# headsail register map
Vendor: tuni.fi; File version: 1.0
CPU: other r1p0, little endian, no MPU, no FPU, vendor SysTick, 2 interrupt priority bits
Registers are 32-bit, read-write, no defined reset value unless marked. A register's access mark holds for its fields unless they carry their own. Offsets are from the block's base; [hi:lo] are bit positions; lines under a group give offsets from that group; {n}, {i} and the like mark numbered series; 'fields as' and 'values as' point back to an identical list.

## SYSCTRL
Base 0x00101000
0x00 GPIO group
  0x00 DIR — GPIO direction configuration bitfield: - bit[i]=1b0: Input mode for GPIO[i] - bit[i]=1b1: Output mode for GPIO[i]
  0x04 EN — GPIO clock enable config register. Bit 31 - 0 GPIOEN (R/W) GPIO[31:0] clock enable configuration bitfield: - bit[i]=1b0: disable clock for GPIO[i] - bit[i]=1b1: enable clock for GPIO[i] GPIOs are gathered by groups of 4. The clock gating of one group is done only if all 4 GPIOs are disabled. Clock must be enabled for a GPIO if its direction is configured in input mode.
    [31:0] GPIOEN
  0x08 IN ro — GPIO Data IN register. Bit 31 - 0 DATA_IN (R) GPIO[31:0] input data read bitfield. DATA_IN[i] corresponds to input data of GPIO[i].
    [31:0] DATA_IN
  0x0C OUT — GPIO Data out register. Bit 31 - 0 DATA_OUT (R/W) GPIO[31:0] output data read bitfield. DATA_OUT[i] corresponds to output data set on GPIO[i].
    [31:0] DATA_OUT
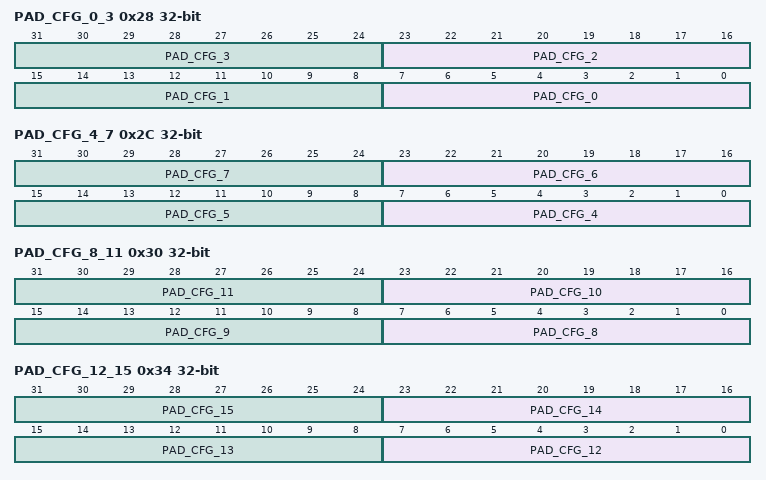
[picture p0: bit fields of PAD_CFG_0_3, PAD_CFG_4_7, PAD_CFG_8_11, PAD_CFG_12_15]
  0x28 PAD_CFG_0_3
    [8n+7:8n] PAD_CFG_{n} (n=0..3)
  0x2C PAD_CFG_4_7
    [8n-25:8n-32] PAD_CFG_{n} (n=4..7)
  0x30 PAD_CFG_8_11
    [8n-57:8n-64] PAD_CFG_{n} (n=8..11)
  0x34 PAD_CFG_12_15
    [8n-89:8n-96] PAD_CFG_{n} (n=12..15)
0x1000 UDMA group
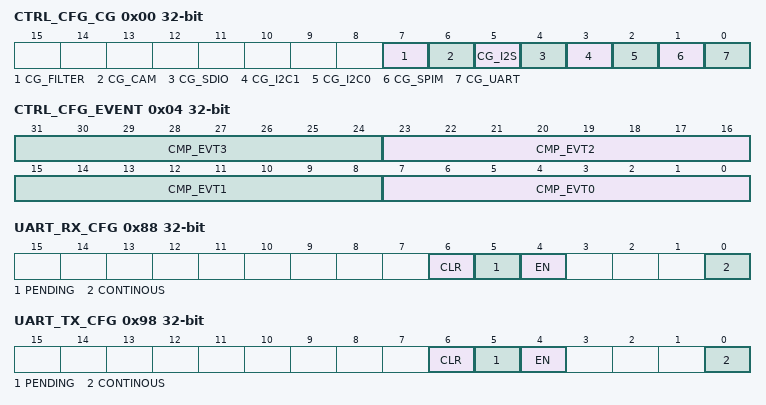
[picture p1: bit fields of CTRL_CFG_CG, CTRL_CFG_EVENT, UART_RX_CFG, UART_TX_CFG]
  0x00 CTRL_CFG_CG — uDMA peripherals clock gate configuration Bitfields Defines uDMA peripherals clock gate configuration for corresponding peripheral
    [7] CG_FILTER, [6] CG_CAM, [5] CG_I2S, [4] CG_SDIO, [3] CG_I2C1, [2] CG_I2C0, [1] CG_SPIM, [0] CG_UART
  0x04 CTRL_CFG_EVENT — uDMA peripherals external event configuration
    [8n+7:8n] CMP_EVT{n} (n=0..3) — Forward event with ID matching CMP_EVT{n} to peripherals as event{n}
  0x08 CTRL_CFG_RST — uDMA peripherals reset trigger (unimplemented)
  0x80 UART_RX_SADDR — uDMA RX UART buffer base address configuration register
    [31:0] RX_SADDR — RX buffer base address bitfield: - Read: returns value of the buffer pointer until transfer is finished. Else returns 0. - Write: sets RX buffer base address
  0x84 UART_RX_SIZE — uDMA RX UART buffer size configuration register
    [16:0] RX_SIZE — RX buffer size bitfield in bytes. (128kBytes maximum) - Read: returns remaining buffer size to transfer. - Write: sets buffer size.
  0x88 UART_RX_CFG — uDMA RX UART stream configuration register
    [6] CLR wo — RX channel clear and stop transfer: -1'b0: disable -1'b1: stop and clear the on-going transfer
    [5] PENDING ro
    [4] EN — RX channel enable and start transfer bitfield: -1'b0: disable -1'b1: enable and start the transfer This signal is used also to queue a transfer if one is already ongoing.
    [0] CONTINOUS — RX channel continuous mode bitfield: -1'b0: disabled -1'b1: enabled At the end of the buffer transfer, the uDMA reloads the address / buffer size and starts a new transfer.
  0x90 UART_TX_SADDR — uDMA TX UART buffer base address configuration register.
    [31:0] TX_SADDR — TX buffer base address bitfield: - Read: returns value of the buffer pointer until transfer is finished. Else returns 0. - Write: sets buffer base address
  0x94 UART_TX_SIZE — uDMA TX UART buffer size configuration register
    [16:0] TX_SIZE — TX buffer size bitfield in bytes. (128kBytes maximum) - Read: returns remaining buffer size to transfer. - Write: sets buffer size.
  0x98 UART_TX_CFG — uDMA TX UART stream configuration register.
    [6] CLR wo — RX channel clear and stop transfer: -1'b0: disable -1'b1: stop and clear the on-going transfer
    [5] PENDING ro — TX transfer pending in queue status flag: -1'b0: no pending transfer in the queue -1'b1: pending transfer in the queue
    [4] EN — TX channel enable and start transfer bitfield: -1'b0: disabled -1'b1: enable and start the transfer This signal is used also to queue a transfer if one is already ongoing.
    [0] CONTINOUS — TX channel continuous mode bitfield: -1'b0: disabled -1'b1: enabled At the end of the buffer transfer, the uDMA reloads the address / buffer size and starts a new transfer.
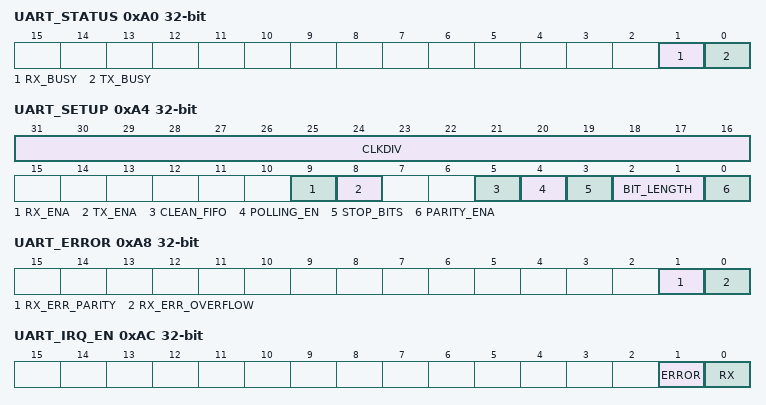
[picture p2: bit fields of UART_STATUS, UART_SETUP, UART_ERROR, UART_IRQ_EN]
  0xA0 UART_STATUS ro — uDMA UART status register
    [1] RX_BUSY — RX busy status flag: - 1'b0: no RX transfer on-going - 1'b1: RX transfer on-going
    [0] TX_BUSY — TX busy status flag: - 1'b0: no TX transfer on-going - 1'b1: TX transfer on-going
  0xA4 UART_SETUP — UDMA UART configuration register.
    [31:16] CLKDIV — UART Clock divider configuration bitfield. The baudrate is equal to SOC_FREQ/CLKDIV.
    [9] RX_ENA — RX transceiver configuration bitfield: - 1'b0: disabled - 1'b1: enabled
    [8] TX_ENA — TX transceiver configuration bitfield: - 1'b0: disabled - 1'b1: enabled
    [5] CLEAN_FIFO — In all mode clean the RX fifo, set 1 then set 0 to realize a reset fifo: - 1'b0: Stop Clean the RX FIFO. - 1'b1: Clean the RX FIFO.
    [4] POLLING_EN — When in uart read, use polling method to read the data, read interrupt enable flag will be ignored: - 1'b0: Do not using polling method to read data. - 1'b1: Using polling method to read data. Interrupt enable flag will be ignored.
    [3] STOP_BITS — Stop bits length bitfield: - 1'b0: 1 stop bit - 1'b1: 2 stop bits
    [2:1] BIT_LENGTH — Character length bitfield: - 2'b00: 5 bits - 2'b01: 6 bits - 2'b10: 7 bits - 2'b11: 8 bits
    [0] PARITY_ENA — Parity bit generation and check configuration bitfield: - 1'b0: disabled - 1'b1: enabled
  0xA8 UART_ERROR ro — uDMA UART Error status
    [1] RX_ERR_PARITY — RX parity error status flag: - 1'b0: no error - 1'b1: RX parity error occurred
    [0] RX_ERR_OVERFLOW — RX overflow error status flag: - 1'b0: no error - 1'b1: RX overflow error occurred
  0xAC UART_IRQ_EN — uDMA UART Read or Error interrupt enable register
    [1] ERROR — Error interrupt in enable flag: - 1'b0: Error IRQ disable - 1'b1: Error IRQ enable
    [0] RX — Rx interrupt in enable flag: - 1'b0: RX IRQ disable - 1'b1: RX IRQ enable
  0xB0 UART_VALID ro — uDMA UART Read polling data valid flag register
    [0] READY — Used only in RX polling method to indicate data is ready for read: - 1'b0: Data is not ready to read - 1'b1: Data is ready to read
  0xB4 UART_DATA ro — RX read data for polling or interrupt
    [7:0] BYTE
  0x100 SPIM_RX_SADDR — RX SPI uDMA transfer address of associated buffer
    [31:0] RX_SADDR — Configure pointer to memory buffer: - Read: value of the pointer until transfer is over. Else returns 0 - Write: set Address Pointer to memory buffer start address
  0x104 SPIM_RX_SIZE — RX SPI uDMA transfer size of buffer
    [19:0] RX_SIZE — Buffer size in bytes. (1MBytes maximum) - Read: buffer size left - Write: set buffer size
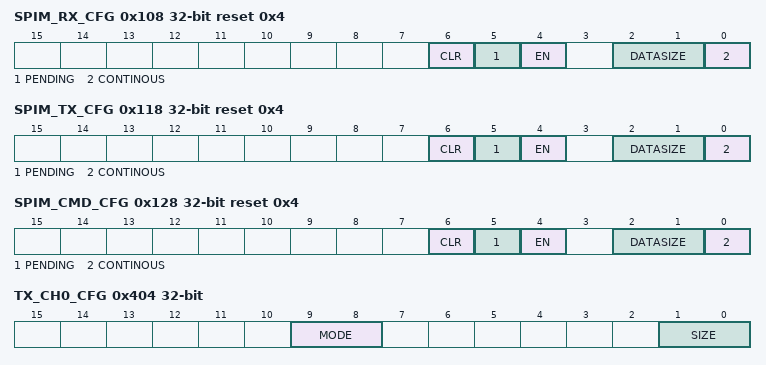
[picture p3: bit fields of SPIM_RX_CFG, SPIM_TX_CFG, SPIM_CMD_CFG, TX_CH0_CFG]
  0x108 SPIM_RX_CFG reset 0x4 (reset mask 0x0) — RX SPI uDMA transfer configuration
    [6] CLR wo — Channel clear and stop transfer: -1'b0: disable -1'b1: enable
    [5] PENDING ro — Transfer pending in queue status flag: -1'b0: free -1'b1: pending
    [4] EN — Channel enable and start transfer: -1'b0: disable -1'b1: enable This signal is used also to queue a transfer if one is already ongoing
    [2:1] DATASIZE — Channel transfer size used to increment uDMA buffer address pointer: - 2'b00: +1 (8 bits) - 2'b01: +2 (16 bits) - 2'b10: +4 (
      0=8BITS; 1=16BITS; 2=32BITS
    [0] CONTINOUS — Channel continuous mode: -1'b0: disable -1'b1: enable At the end of the buffer the uDMA reloads the address and size and starts a new transfer.
  0x110 SPIM_TX_SADDR — TX SPI uDMA transfer address of associated buffer
    [31:0] TX_SADDR — Configure pointer to memory buffer: - Read: value of the pointer until transfer is over. Else returns 0 - Write: set Address Pointer to memory buffer start address
  0x114 SPIM_TX_SIZE — TX SPI uDMA transfer size of buffer
    [19:0] TX_SIZE — Buffer size in bytes. (1MBytes maximum) - Read: buffer size left - Write: set buffer size
  0x118 SPIM_TX_CFG reset 0x4 (reset mask 0x0) — TX SPI uDMA transfer configuration
    fields as UDMA.SPIM_RX_CFG
  0x120 SPIM_CMD_SADDR — CMD SPI uDMA transfer address of associated buffer
    [31:0] CMD_SADDR — Configure pointer to memory buffer: - Read: value of the pointer until transfer is over. Else returns 0 - Write: set Address Pointer to memory buffer start address
  0x124 SPIM_CMD_SIZE — CMD SPI uDMA transfer size of buffer
    [19:0] CMD_SIZE — Buffer size in bytes. (1MBytes maximum) - Read: buffer size left - Write: set buffer size
  0x128 SPIM_CMD_CFG reset 0x4 (reset mask 0x0) — CMD SPI uDMA transfer configuration
    fields as UDMA.SPIM_RX_CFG
  0x400 TX_CH0_ADD — FILTER tx channel address register
    [31:0] REG_TX_CH0_ADD
  0x404 TX_CH0_CFG — FILTER tx channel configuration register
    [9:8] MODE — Data transfer mode: - 2'b00: Linear - 2'b01: Sliding - 2;b10:Circular - 2;b11:2D
      0=LINEAR; 1=SLIDING; 2=CIRCULAR; 3=2D
    [1:0] SIZE — Data transfer format: - 2'b00: 8-bit - 2'b01:16-bit - 2;b10:32-bit
      0=8BITS; 1=16BITS; 2=32BITS
  0x408 TX_CH0_LEN0 — FILTER tx channel length1 register
    [31:0] REG_TX_CH0_ADD
  0x40C TX_CH0_LEN1 — FILTER tx channel length2 register
    [31:0] REG_TX_CH0_LEN1
  0x410 TX_CH0_LEN2 — FILTER tx channel 0 length2 register
    [31:0] REG_TX_CH0_LEN2
  0x414 TX_CH1_ADD — FILTER tx channel address register
    [31:0] REG_TX_CH1_ADD
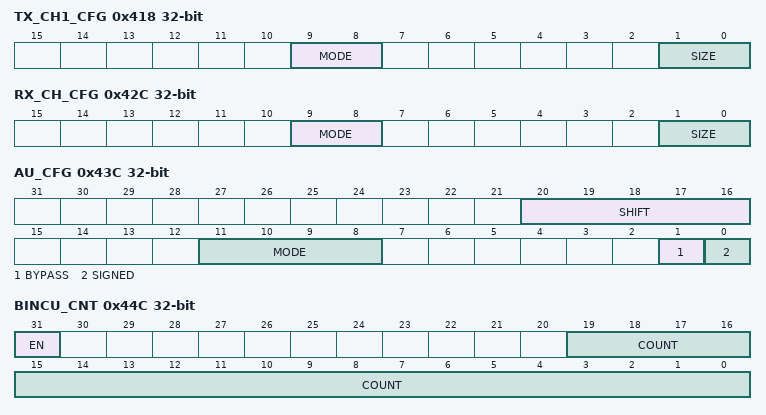
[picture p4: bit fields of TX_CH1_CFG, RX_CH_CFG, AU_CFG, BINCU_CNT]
  0x418 TX_CH1_CFG — FILTER tx channel configuration register
    [9:8] MODE — Data transfer mode: - 2'b00: Linear - 2'b01: Sliding - 2;b10:Circular - 2;b11:2D
      1=SLIDING; 0=LINEAR; 2=CIRCULAR; 3=2D
    [1:0] SIZE — Data transfer format: - 2'b00: 8-bit - 2'b01:16-bit - 2;b10:32-bit
      0=8BITS; 1=16BITS; 2=32BITS
  0x41C TX_CH1_LEN0 — FILTER tx channel length1 register
    [31:0] REG_TX_CH1_ADD
  0x420 TX_CH1_LEN1 — FILTER tx channel length2 register
    [31:0] REG_TX_CH1_LEN1
  0x424 TX_CH1_LEN2 — FILTER RX channel configuration register
    [31:0] REG_TX_CH1_LEN2
  0x428 RX_CH_ADD — FILTER RX channel address register
    [31:0] REG_RX_CH_ADD
  0x42C RX_CH_CFG — FILTER RX channel configuration register
    fields as UDMA.TX_CH1_CFG
  0x430 RX_CH_LEN0 — FILTER RX channel configuration register
    [31:0] REG_RX_CH_LEN0
  0x434 RX_CH_LEN1 — FILTER RX channel length1 register
    [31:0] REG_RX_CH_LEN1
  0x438 RX_CH_LEN2 — FILTER RX channel length2 register
    [31:0] REG_RX_CH_LEN2
  0x43C AU_CFG — FILTER arithmetic unit configuration register
    [20:16] SHIFT — Arithmetic Unit shift window size, (0 – 31).
    [11:8] MODE — Arithmetic Unit mode: -4'b0000: AU_MODE_AxB -4'b0001: AU_MODE_AxB+REG0 -4'b0010: AU_MODE_AxB accumulation -4'b0011: AU_MODE_AxA -4'b0100: AU_MODE_AxA+B -4'b0101: AU_MODE_AxA-B -4'b0110: AU_MODE_AxA accumulation -4'b0111: AU_MODE_AxA+REG0 -4'b1000: AU_MODE_AxREG1 -4'b1001: AU_MODE_AxREG1+B -4'b1010: AU_MODE_AxREG1-B -4'b1011: AU_MODE_AxREG1+REG0 -4'b1100: AU_MODE_AxREG1 accumulation -4'b1101: AU_MODE_A+B -4'b1110: AU_MODE_A-B -4'b1111: AU_MODE_A+REG0
      0=AU_MODE_AxB; 1=AU_MODE_AxBplusREG0; 2=AU_MODE_AxB_accumulation; 3=AU_MODE_AxA; 4=AU_MODE_AxAplusB; 5=AU_MODE_AxAminusB; 6=AU_MODE_AxA_accumulation; 7=AU_MODE_AxAplusREG0; 8=AU_MODE_AxREG1; 9=AU_MODE_AxREG1plusB; 10=AU_MODE_AxREG1minusB; 11=AU_MODE_AxREG1plusREG0; 12=AU_MODE_AxREG1_accumulation; 13=AU_MODE_AplusB; 14=AU_MODE_AminusB; 15=AU_MODE_AplusREG0
    [1] BYPASS — Arithmetic Unit bypass or not. -1'b0: not bypass AU -1'b1: bypass AU
    [0] SIGNED — Arithmetic Unit result signed or not. -1'b0: not signed -1'b1: signed
      0=NOT_SIGNED; 1=SIGNED
  0x440 AU_REG0 — FILTER arithmetic unit 0 register
    [31:0] REG_AU_REG0
  0x444 AU_REG1 — FILTER arithmetic unit 1 register
    [31:0] REG_AU_REG1
  0x448 BINCU_TH — FILTER binarization threshold register
    [31:0] REG_BINCU_TH
  0x44C BINCU_CNT — FILTER binarization count register
    [31] EN — Binarization and counting unit enable: -1'b0: not enable -1'b1: enable
    [19:0] COUNT — Binarization and counting unit count value set.
  0x450 BINCU_SETUP — FILTER binarization result count register
    [31:0] REG_BINCU_SETUP
  0x454 BINCU_VAL ro — FILTER binarization result count register
    [31:0] REG_BINCU_VAL
  0x458 FILT — FILTER control mode register
    [31:0] REG_FILT
  0x45C FILT_CMD — FILTER start register
    [0] START — Filter start flag, write only, write 1 to start the filter :
  0x460 FILT_STATUS — FILTER status register
    [0] DONE — Filter done flag, write 1 to clear the flag : -1'b0: Filter process is not finished -1'b1: Filter process is finished
0x3000 SocControl group
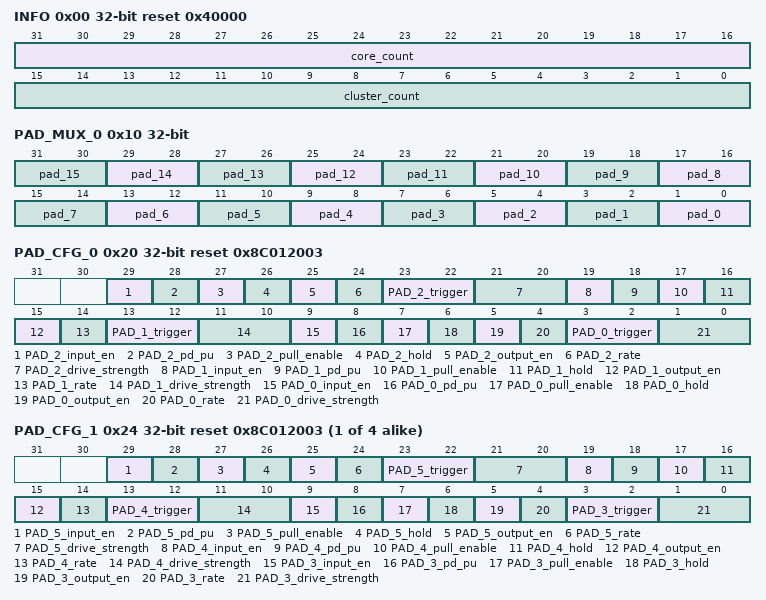
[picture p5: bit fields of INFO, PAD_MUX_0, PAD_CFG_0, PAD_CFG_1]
  0x00 INFO ro reset 0x40000 (reset mask 0x0) — This register holds the number of clusters and the number of cores in the each cluster. It is a read-only register.
    [31:16] core_count — Number of Cores
    [15:0] cluster_count — Number of Clusters
  0x04 FCBOOT reset 0x1A000080 (reset mask 0x0) — This register holds the boot address.
    [31:0] FCBOOT — Boot Start address
  0x08 FCFETCH wo reset 0x1 (reset mask 0x0) — This register contains the value of the fetch enable signal of the core.
    [0] FCFETCH — Enable Fetch, 1 to enable core execution
  0x10 PAD_MUX_0 — The content of these registers can be used to multiplex pads when targeting an ASIC. The first register (0x1A10_4010) can be used to set the mux (2 bit select) from pin 0 (bits [1:0]) to 15 (bits [31:30]).
    [2n+1:2n] pad_{n} (n=0..15)
  0x20 PAD_CFG_0 reset 0x8C012003 (reset mask 0x0) — All 10 bit fields have reset value of 10'b10_0011_0100: 0 drive strenght 1 drive strenght 2 trigger 3 trigger 4 rate 5 output en(0) 6 hold 7 pull enable 8 pd(0)/pu(1) 9 input en(1)
    [29] PAD_2_input_en
    [28] PAD_2_pd_pu — Pull down or pull up register, default pull down 0: pull down 1: pull up
    [27] PAD_2_pull_enable
    [26] PAD_2_hold
    [25] PAD_2_output_en — 0: Enable
    [24] PAD_2_rate
    [23:22] PAD_2_trigger
    [21:20] PAD_2_drive_strength
    [19] PAD_1_input_en
    [18] PAD_1_pd_pu — Pull down or pull up register, default pull down 0: pull down 1: pull up
    [17] PAD_1_pull_enable
    [16] PAD_1_hold
    [15] PAD_1_output_en — 0: Enable
    [14] PAD_1_rate
    [13:12] PAD_1_trigger
    [11:10] PAD_1_drive_strength
    [9] PAD_0_input_en
    [8] PAD_0_pd_pu — Pull down or pull up register, default pull down 0: pull down 1: pull up
    [7] PAD_0_pull_enable
    [6] PAD_0_hold
    [5] PAD_0_output_en — 0: Enable
    [4] PAD_0_rate
    [3:2] PAD_0_trigger
    [1:0] PAD_0_drive_strength
  {0x20+4j} PAD_CFG_{j} access not given reset 0x8C012003 (reset mask 0x0) (j=1..4)
    [29] PAD_{3j+2}_input_en
    [28] PAD_{3j+2}_pd_pu — Pull down or pull up register, default pull down 0: pull down 1: pull up
    [27] PAD_{3j+2}_pull_enable
    [26] PAD_{3j+2}_hold
    [25] PAD_{3j+2}_output_en — 0: Enable
    [24] PAD_{3j+2}_rate
    [23:22] PAD_{3j+2}_trigger
    [21:20] PAD_{3j+2}_drive_strength
    [19] PAD_{3j+1}_input_en
    [18] PAD_{3j+1}_pd_pu — Pull down or pull up register, default pull down 0: pull down 1: pull up
    [17] PAD_{3j+1}_pull_enable
    [16] PAD_{3j+1}_hold
    [15] PAD_{3j+1}_output_en — 0: Enable
    [14] PAD_{3j+1}_rate
    [13:12] PAD_{3j+1}_trigger
    [11:10] PAD_{3j+1}_drive_strength
    [9] PAD_{3j}_input_en
    [8] PAD_{3j}_pd_pu — Pull down or pull up register, default pull down 0: pull down 1: pull up
    [7] PAD_{3j}_pull_enable
    [6] PAD_{3j}_hold
    [5] PAD_{3j}_output_en — 0: Enable
    [4] PAD_{3j}_rate
    [3:2] PAD_{3j}_trigger
    [1:0] PAD_{3j}_drive_strength
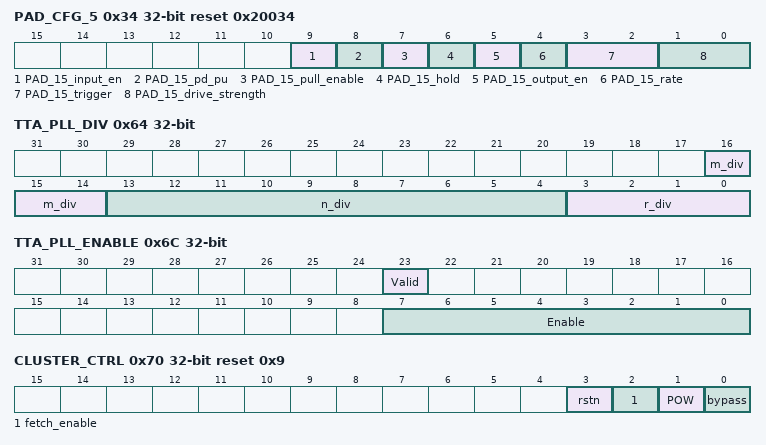
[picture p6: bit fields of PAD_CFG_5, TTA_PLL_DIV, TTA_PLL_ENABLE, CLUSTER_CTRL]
  0x34 PAD_CFG_5 access not given reset 0x20034 (reset mask 0x0)
    [9] PAD_15_input_en
    [8] PAD_15_pd_pu — Pull down or pull up register, default pull down 0: pull down 1: pull up
    [7] PAD_15_pull_enable
    [6] PAD_15_hold
    [5] PAD_15_output_en — 0: Enable
    [4] PAD_15_rate
    [3:2] PAD_15_trigger
    [1:0] PAD_15_drive_strength
  0x60 TTA_PLL_LOOP_CTRL
    [31:0] LOOP_CTRL
  0x64 TTA_PLL_DIV
    [16:14] m_div, [13:4] n_div, [3:0] r_div
  0x68 TTA_PLL_DEBUG_CTRL
    [7:0] Debug_Ctrl
  0x6C TTA_PLL_ENABLE
    [23] Valid, [7:0] Enable
  0x70 CLUSTER_CTRL reset 0x9 (reset mask 0x0)
    [3] rstn, [2] fetch_enable, [1] POW, [0] bypass
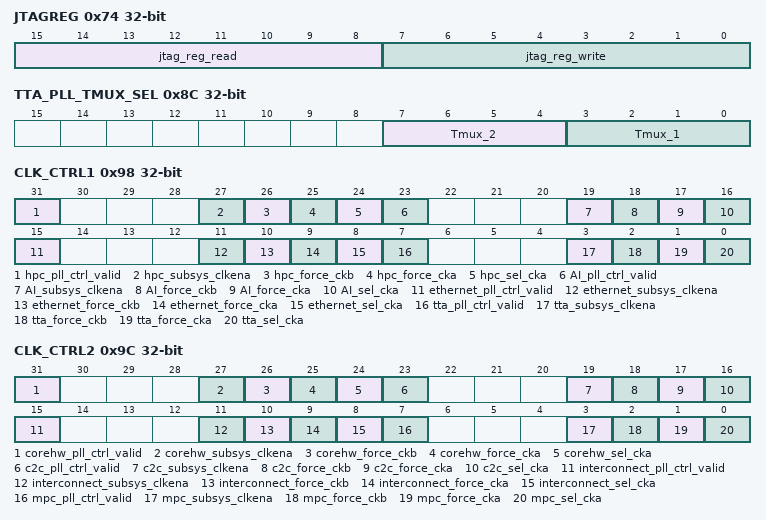
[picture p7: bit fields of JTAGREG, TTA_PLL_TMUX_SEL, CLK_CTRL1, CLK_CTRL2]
  0x74 JTAGREG — Register to read or write from JTAG
    [15:8] jtag_reg_read, [7:0] jtag_reg_write
  0x78 CTRL_PER
    [0] Sel_hyper_axi
  0x7C CLUSTER_IRQ
    [0] Cluster_IRQ
  0x80 CLUSTER_BOOT_ADDR0
  0x84 CLUSTER_BOOT_ADDR1
  0x88 TTA_PLL_SPARE_CTRL
    [31:0] spare_ctrl
  0x8C TTA_PLL_TMUX_SEL
    [7:4] Tmux_2, [3:0] Tmux_1
  0x90 TTA_PLL_STATUS1 ro
  0x94 TOPPERIPH_CLK_DIV
    [15:0] REG_TOPPERIPH_CLK_DIV — Clock divider ratio for Top peripheral module
  0x98 CLK_CTRL1 — Subsystem Clock selection. Bit definition for TTA, Ethernet, AI, HPC subsystems *_CLK_CTRL Bitfield definitions [bit]:[field] 0: sel_cka 1: force_cka 2: force_ckb 3: subsys_clkena 4: - 5: - 6: - 7: pll_ctrl_valid
    [31] hpc_pll_ctrl_valid — PLL Control valid
    [27] hpc_subsys_clkena — Subsystem clock enable
    [26] hpc_force_ckb — Force CKB
    [25] hpc_force_cka — Force CKA
    [24] hpc_sel_cka — Select CKA
    [23] AI_pll_ctrl_valid — PLL Control valid
    [19] AI_subsys_clkena — Subsystem clock enable
    [18] AI_force_ckb — Force CKB
    [17] AI_force_cka — Force CKA
    [16] AI_sel_cka — Select CKA
    [15] ethernet_pll_ctrl_valid — PLL Control valid
    [11] ethernet_subsys_clkena — Subsystem clock enable
    [10] ethernet_force_ckb — Force CKB
    [9] ethernet_force_cka — Force CKA
    [8] ethernet_sel_cka — Select CKA
    [7] tta_pll_ctrl_valid — PLL Control valid
    [3] tta_subsys_clkena — Subsystem clock enable
    [2] tta_force_ckb — Force CKB
    [1] tta_force_cka — Force CKA
    [0] tta_sel_cka — Select CKA
  0x9C CLK_CTRL2 — Subsystem Clock selection. Bit definition for MPC, Interconnect, C2C and CoreHW subsystems *_CLK_CTRL Bitfield definitions [bit]:[field] 0: sel_cka 1: force_cka 2: force_ckb 3: subsys_clkena 4: - 5: - 6: - 7: pll_ctrl_valid
    [31] corehw_pll_ctrl_valid — PLL Control valid
    [27] corehw_subsys_clkena — Subsystem clock enable
    [26] corehw_force_ckb — Force CKB
    [25] corehw_force_cka — Force CKA
    [24] corehw_sel_cka — Select CKA
    [23] c2c_pll_ctrl_valid — PLL Control valid
    [19] c2c_subsys_clkena — Subsystem clock enable
    [18] c2c_force_ckb — Force CKB
    [17] c2c_force_cka — Force CKA
    [16] c2c_sel_cka — Select CKA
    [15] interconnect_pll_ctrl_valid — PLL Control valid
    [11] interconnect_subsys_clkena — Subsystem clock enable
    [10] interconnect_force_ckb — Force CKB
    [9] interconnect_force_cka — Force CKA
    [8] interconnect_sel_cka — Select CKA
    [7] mpc_pll_ctrl_valid — PLL Control valid
    [3] mpc_subsys_clkena — Subsystem clock enable
    [2] mpc_force_ckb — Force CKB
    [1] mpc_force_cka — Force CKA
    [0] mpc_sel_cka — Select CKA
  0xA0 CORESTATUS — These 2 registers (CORESTATUS, CS_RO) contain the status of the system for testing/verification purposes like End Of Computation. The 0x1A10_40C0 register is read-only.
    [1:0] CORE_STATUS
  0xA4 SLOW_PULSE_DIV
    [9:0] SLOW_PULSE_DIV
  0xA8 PERIPH_CLK_DIV
    [9:0] PERIPH_CLK_DIV
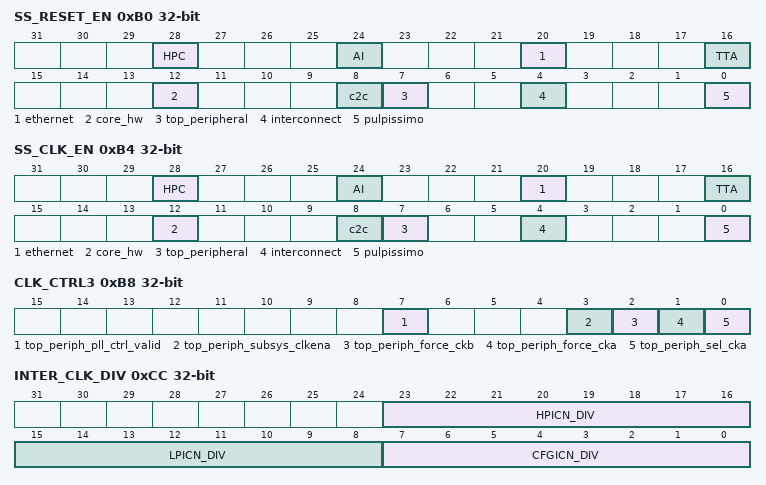
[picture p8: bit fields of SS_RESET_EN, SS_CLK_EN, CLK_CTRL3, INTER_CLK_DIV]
  0xB0 SS_RESET_EN — Assertion of the Subsystem bit, deasserts the reset to the corresponding subsystem. Bit definition is mentioned in adjoining table
    [28] HPC — HPC subsystem reset enable
    [24] AI — AI subsystem reset enable
    [20] ethernet — Ethernet subsystem reset enable
    [16] TTA — TTA Reset enable
    [12] core_hw — coreHW reset enable
    [8] c2c — C2C reset enable
    [7] top_peripheral — Top Peripheral reset enable
    [4] interconnect — interconnect subsystem reset enable
    [0] pulpissimo — Pulpissimo subsystem reset enable
  0xB4 SS_CLK_EN — Subsystem clock enable register
    [28] HPC — HPC subsystem clock enable
    [24] AI — AI subsystem clock enable
    [20] ethernet — Ethernet subsystem clock enable
    [16] TTA — TTA subsystem clock enable
    [12] core_hw — coreHW subsystem clock enable
    [8] c2c — C2C clock enable
    [7] top_peripheral — Top Peripheral subsystem clock enable
    [4] interconnect — interconnect subsystem clock enable
    [0] pulpissimo — Pulpissimo subsystem clock enable
  0xB8 CLK_CTRL3 — Subsystem Clock selection. Bit definition for Top peripheral subsystem. *_CLK_CTRL Bitfield definitions [bit]:[field] 0: sel_cka 1: force_cka 2: force_ckb 3: subsys_clkena 4: - 5: - 6: - 7: pll_ctrl_valid
    [7] top_periph_pll_ctrl_valid — PLL Control valid
    [3] top_periph_subsys_clkena — Subsystem clock enable
    [2] top_periph_force_ckb — Force CKB
    [1] top_periph_force_cka — Force CKA
    [0] top_periph_sel_cka — Select CKA
  0xBC TTA_PLL_STATUS2 ro
  0xC0 CS_RO ro
  0xC4 BOOTSEL ro — Boot Sel value
    [31:0] bootsel_pad
  0xC8 CLKSEL ro
    [31:0] CLKSEL — Irrelevant. Select FLL clock. Sysctrl does not have FLL
  0xCC INTER_CLK_DIV — Clock divider ratio for the 3 Interconnect modules
    [23:16] HPICN_DIV, [15:8] LPICN_DIV, [7:0] CFGICN_DIV
0x30D0 ETH_PLL group
  0x00 ETH_PLL_LOOP_CTRL
    [31:0] LOOP_CTRL
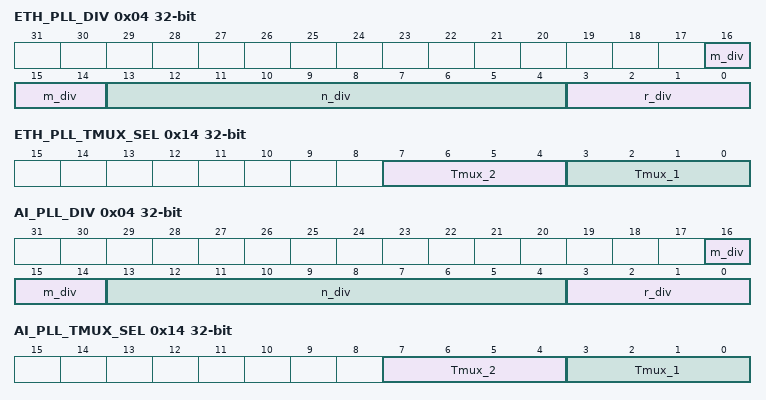
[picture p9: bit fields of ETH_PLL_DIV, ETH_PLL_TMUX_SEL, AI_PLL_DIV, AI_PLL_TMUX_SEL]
  0x04 ETH_PLL_DIV
    [16:14] m_div, [13:4] n_div, [3:0] r_div
  0x08 ETH_PLL_DEBUG_CTRL
    [7:0] Debug_Ctrl
  0x0C ETH_PLL_ENABLE
    [31:0] spare_ctrl
  0x10 ETH_PLL_SPARE_CTRL
    [31:0] spare_ctrl
  0x14 ETH_PLL_TMUX_SEL
    [7:4] Tmux_2, [3:0] Tmux_1
  0x18 ETH_PLL_STATUS1 ro
  0x1C ETH_PLL_STATUS2 ro
0x30F0 AI_PLL group
  0x00 AI_PLL_LOOP_CTRL
    [31:0] LOOP_CTRL
  0x04 AI_PLL_DIV
    [16:14] m_div, [13:4] n_div, [3:0] r_div
  0x08 AI_PLL_DEBUG_CTRL
    [7:0] Debug_Ctrl
  0x0C AI_PLL_ENABLE
    [31:0] spare_ctrl
  0x10 AI_PLL_SPARE_CTRL
    [31:0] spare_ctrl
  0x14 AI_PLL_TMUX_SEL
    [7:4] Tmux_2, [3:0] Tmux_1
  0x18 AI_PLL_STATUS1 ro
  0x1C AI_PLL_STATUS2 ro
0x3110 HPC_PLL group
  0x00 HPC_PLL_LOOP_CTRL
    [31:0] LOOP_CTRL
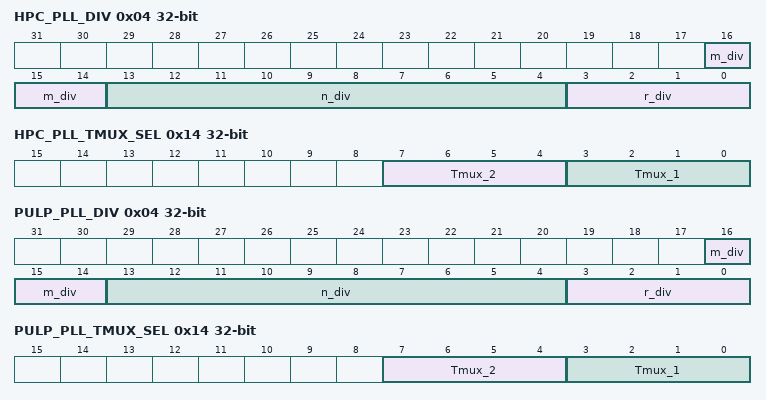
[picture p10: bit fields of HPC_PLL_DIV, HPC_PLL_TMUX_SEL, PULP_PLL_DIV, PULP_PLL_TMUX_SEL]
  0x04 HPC_PLL_DIV
    [16:14] m_div, [13:4] n_div, [3:0] r_div
  0x08 HPC_PLL_DEBUG_CTRL
    [7:0] Debug_Ctrl
  0x0C HPC_PLL_ENABLE
    [31:0] spare_ctrl
  0x10 HPC_PLL_SPARE_CTRL
    [31:0] spare_ctrl
  0x14 HPC_PLL_TMUX_SEL
    [7:4] Tmux_2, [3:0] Tmux_1
  0x18 HPC_PLL_STATUS1 ro
  0x1C HPC_PLL_STATUS2 ro
0x3130 PULP_PLL group
  0x00 PULP_PLL_LOOP_CTRL
    [31:0] LOOP_CTRL
  0x04 PULP_PLL_DIV
    [16:14] m_div, [13:4] n_div, [3:0] r_div
  0x08 PULP_PLL_DEBUG_CTRL
    [7:0] Debug_Ctrl
  0x0C PULP_PLL_ENABLE
    [31:0] spare_ctrl
  0x10 PULP_PLL_SPARE_CTRL
    [31:0] spare_ctrl
  0x14 PULP_PLL_TMUX_SEL
    [7:4] Tmux_2, [3:0] Tmux_1
  0x18 PULP_PLL_STATUS1 ro
  0x1C PULP_PLL_STATUS2 ro
0x3150 INTER_PLL group
  0x00 INTER_PLL_LOOP_CTRL
    [31:0] LOOP_CTRL
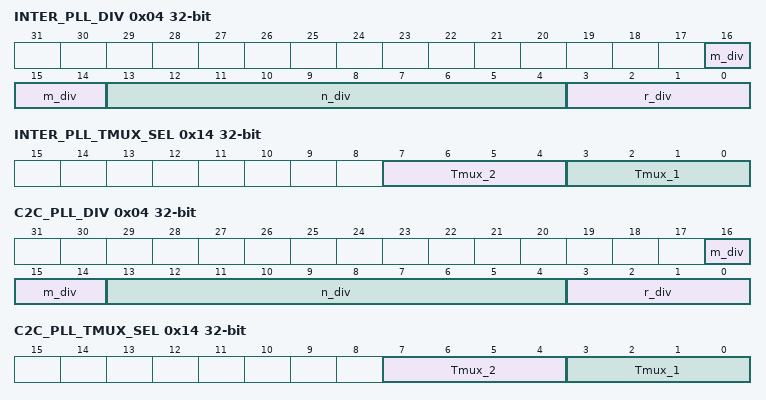
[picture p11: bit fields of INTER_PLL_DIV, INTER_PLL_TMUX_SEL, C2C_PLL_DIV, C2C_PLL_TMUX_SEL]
  0x04 INTER_PLL_DIV
    [16:14] m_div, [13:4] n_div, [3:0] r_div
  0x08 INTER_PLL_DEBUG_CTRL
    [7:0] Debug_Ctrl
  0x0C INTER_PLL_ENABLE
    [31:0] spare_ctrl
  0x10 INTER_PLL_SPARE_CTRL
    [31:0] spare_ctrl
  0x14 INTER_PLL_TMUX_SEL
    [7:4] Tmux_2, [3:0] Tmux_1
  0x18 INTER_PLL_STATUS1 ro
  0x1C INTER_PLL_STATUS2 ro
0x3170 C2C_PLL group
  0x00 C2C_PLL_LOOP_CTRL
    [31:0] LOOP_CTRL
  0x04 C2C_PLL_DIV
    [16:14] m_div, [13:4] n_div, [3:0] r_div
  0x08 C2C_PLL_DEBUG_CTRL
    [7:0] Debug_Ctrl
  0x0C C2C_PLL_ENABLE
    [31:0] spare_ctrl
  0x10 C2C_PLL_SPARE_CTRL
    [31:0] spare_ctrl
  0x14 C2C_PLL_TMUX_SEL
    [7:4] Tmux_2, [3:0] Tmux_1
  0x18 C2C_PLL_STATUS1 ro
  0x1C C2C_PLL_STATUS2 ro
0x31B0 TOPPERIPH_PLL group
  0x00 TOPPERIPH_PLL_LOOP_CTRL
    [31:0] LOOP_CTRL
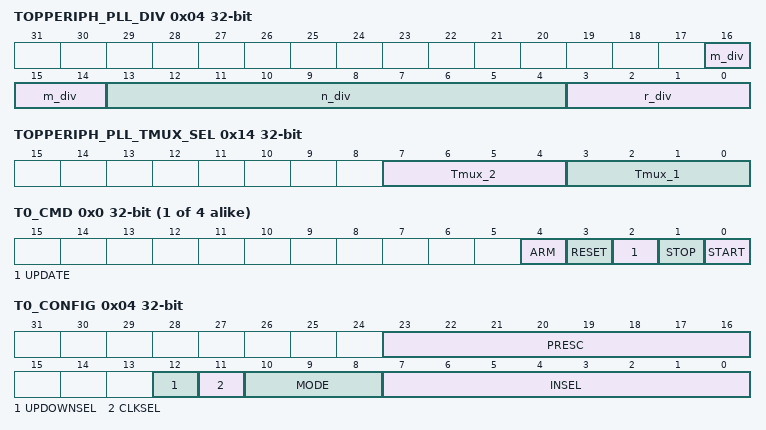
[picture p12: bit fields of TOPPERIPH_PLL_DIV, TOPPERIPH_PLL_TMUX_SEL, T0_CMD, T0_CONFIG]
  0x04 TOPPERIPH_PLL_DIV
    [16:14] m_div, [13:4] n_div, [3:0] r_div
  0x08 TOPPERIPH_PLL_DEBUG_CTRL
    [7:0] Debug_Ctrl
  0x0C TOPPERIPH_PLL_ENABLE
    [31:0] spare_ctrl
  0x10 TOPPERIPH_PLL_SPARE_CTRL
    [31:0] spare_ctrl
  0x14 TOPPERIPH_PLL_TMUX_SEL
    [7:4] Tmux_2, [3:0] Tmux_1
  0x18 TOPPERIPH_PLL_STATUS1 ro
  0x1C TOPPERIPH_PLL_STATUS2 ro
0x31D0 BootConfig group
  0x00 BOOT_CFG
    [31:0] REG_BOOT_CFG
  0x04 BOOT_STATUS
    [31:0] REG_BOOT_STATUS
0x4000 AdvancedTimer group
  {0x0+0x40*j} T{j}_CMD (j=0..3) — ADV_TIMER{j} command register
    [4] ARM — ADV_TIMER{j} arm command bitfield.
    [3] RESET — ADV_TIMER{j} reset command bitfield
    [2] UPDATE — ADV_TIMER{j} update command bitfield.
    [1] STOP — ADV_TIMER{j} stop command bitfield.
    [0] START — ADV_TIMER{j} start command bitfield
  0x04 T0_CONFIG — ADV_TIMER0 configuration register.
    [23:16] PRESC — ADV_TIMER0 prescaler value configuration bitfield.
    [12] UPDOWNSEL — ADV_TIMER0 center-aligned mode configuration bitfield: - 1'b0: The counter counts up and down alternatively. - 1'b1: The counter counts up and resets to 0 when reach threshold.
    [11] CLKSEL — ADV_TIMER0 clock source configuration bitfield: - 1'b0: FLL - 1'b1: reference clock at 32kHz
    [10:8] MODE — ADV_TIMER0 trigger mode configuration bitfield: - 3'h0: trigger event at each clock cycle. - 3'h1: trigger event if input source is 0 - 3'h2: trigger event if input source is 1 - 3'h3: trigger event on input source rising edge - 3'h4: trigger event on input source falling edge - 3'h5: trigger event on input source falling or rising edge - 3'h6: trigger event on input source rising edge when armed - 3'h7: trigger event on input source falling edge when armed
    [7:0] INSEL — ADV_TIMER0 input source configuration bitfield: - 0-31: GPIO[0] to GPIO[31] - 32-35: Channel 0 to 3 of ADV_TIMER0 - 36-39: Channel 0 to 3 of ADV_TIMER1 - 40-43: Channel 0 to 3 of ADV_TIMER2 - 44-47: Channel 0 to 3 of ADV_TIMER3
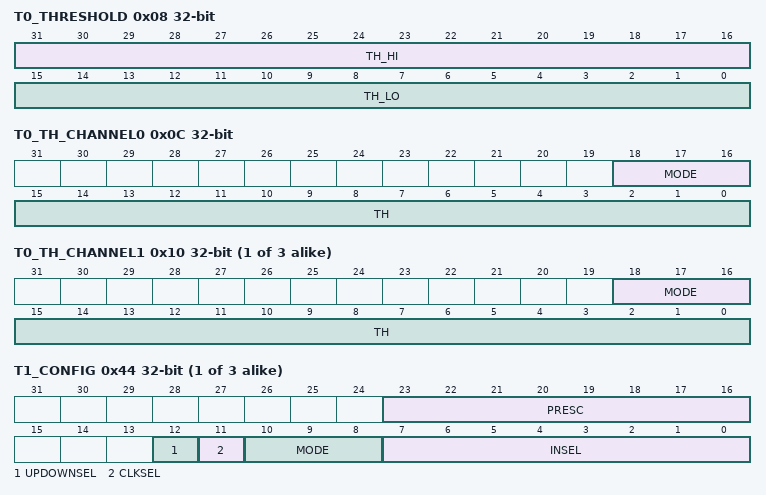
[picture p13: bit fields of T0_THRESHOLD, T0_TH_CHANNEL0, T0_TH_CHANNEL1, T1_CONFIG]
  0x08 T0_THRESHOLD — ADV_TIMER0 threshold configuration register.
    [31:16] TH_HI — ADV_TIMER0 threshold high part configuration bitfield. It defines end counter value.
    [15:0] TH_LO — ADV_TIMER0 threshold low part configuration bitfield. It defines start counter value
  0x0C T0_TH_CHANNEL0 — ADV_TIMER0 channel 0 threshold configuration register
    [18:16] MODE — ADV_TIMER0 channel 0 threshold match action on channel output signal configuration bitfield: - 3'h0: set. - 3'h1: toggle then next threshold match action is clear. - 3'h2: set then next threshold match action is clear. - 3'h3: toggle. - 3'h4: clear. - 3'h5: toggle then next threshold match action is set. - 3'h6: clear then next threshold match action is set.
      0=SET; 1=TOGGLE_CLEAR_NEXT; 2=SET_CLEAR_NEXT; 3=TOGGLE; 4=CLEAR; 5=TOGGLE_SET_NEXT; 6=CLEAR_SET_NEXT
    [15:0] TH — ADV_TIMER0 channel 0 threshold configuration bitfield
  {0xC+4j} T0_TH_CHANNEL{j} (j=1..3) — ADV_TIMER0 channel {j} threshold configuration register
    [18:16] MODE — ADV_TIMER0 channel {j} threshold match action on channel output signal configuration bitfield: - 3'h0: set. - 3'h1: toggle then next threshold match action is clear. - 3'h2: set then next threshold match action is clear. - 3'h3: toggle. - 3'h4: clear. - 3'h5: toggle then next threshold match action is set. - 3'h6: clear then next threshold match action is set.
      5=TOGGLE_SET_NEXT; 1=TOGGLE_CLEAR_NEXT; 3=TOGGLE; 2=SET_CLEAR_NEXT; 0=SET; 6=CLEAR_SET_NEXT; 4=CLEAR
    [15:0] TH — ADV_TIMER0 channel {j} threshold configuration bitfield
  0x2C T0_COUNTER ro — ADV_TIMER0 counter register
  {0x4+0x40*j} T{j}_CONFIG (j=1..3) — ADV_TIMER{j} configuration register
    [23:16] PRESC — ADV_TIMER{j} prescaler value configuration bitfield.
    [12] UPDOWNSEL — ADV_TIMER{j} center-aligned mode configuration bitfield: - 1'b0: The counter counts up and down alternatively. - 1'b1: The counter counts up and resets to 0 when reach threshold.
    [11] CLKSEL — ADV_TIMER{j} clock source configuration bitfield: - 1'b0: FLL - 1'b1: reference clock at 32kHz
    [10:8] MODE — ADV_TIMER{j} trigger mode configuration bitfield: - 3'h0: trigger event at each clock cycle. - 3'h1: trigger event if input source is 0 - 3'h2: trigger event if input source is 1 - 3'h3: trigger event on input source rising edge - 3'h4: trigger event on input source falling edge - 3'h5: trigger event on input source falling or rising edge - 3'h6: trigger event on input source rising edge when armed - 3'h7: trigger event on input source falling edge when armed
    [7:0] INSEL — ADV_TIMER{j} input source configuration bitfield: - 0-31: GPIO[0] to GPIO[31] - 32-35: Channel 0 to 3 of ADV_TIMER0 - 36-39: Channel 0 to 3 of ADV_TIMER1 - 40-43: Channel 0 to 3 of ADV_TIMER2 - 44-47: Channel 0 to 3 of ADV_TIMER3
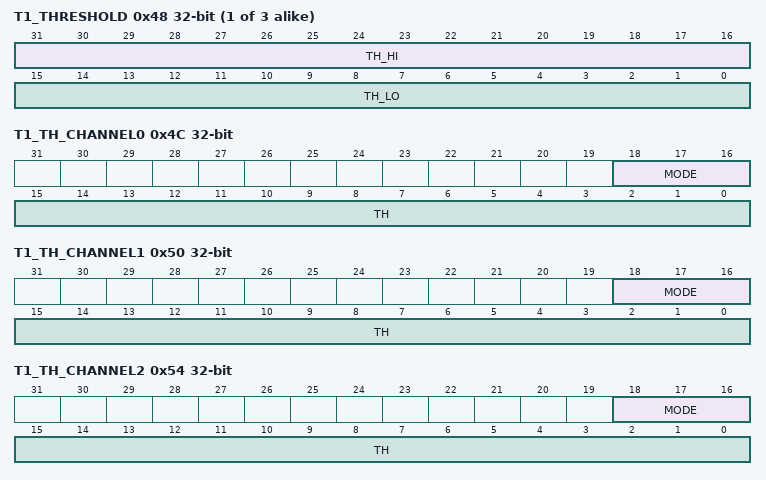
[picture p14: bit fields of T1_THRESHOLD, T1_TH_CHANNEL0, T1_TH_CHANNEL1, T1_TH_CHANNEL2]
  {0x8+0x40*j} T{j}_THRESHOLD (j=1..3) — ADV_TIMER{j} threshold configuration register
    [31:16] TH_HI — ADV_TIMER{j} threshold high part configuration bitfield. It defines end counter value.
    [15:0] TH_LO — ADV_TIMER{j} threshold low part configuration bitfield. It defines start counter value
  0x4C T1_TH_CHANNEL0 — ADV_TIMER1 channel 0 threshold configuration register
    [18:16] MODE — ADV_TIMER1 channel 0 threshold match action on channel output signal configuration bitfield: - 3'h0: set. - 3'h1: toggle then next threshold match action is clear. - 3'h2: set then next threshold match action is clear. - 3'h3: toggle. - 3'h4: clear. - 3'h5: toggle then next threshold match action is set. - 3'h6: clear then next threshold match action is set.
      values as AdvancedTimer.T0_TH_CHANNEL1.MODE
    [15:0] TH — ADV_TIMER1 channel 0 threshold configuration bitfield
  0x50 T1_TH_CHANNEL1 — ADV_TIMER1 channel 1 threshold configuration register
    [18:16] MODE — ADV_TIMER1 channel 1 threshold match action on channel output signal configuration bitfield: - 3'h0: set. - 3'h1: toggle then next threshold match action is clear. - 3'h2: set then next threshold match action is clear. - 3'h3: toggle. - 3'h4: clear. - 3'h5: toggle then next threshold match action is set. - 3'h6: clear then next threshold match action is set.
      2=SET_CLEAR_NEXT; 4=CLEAR; 0=SET; 5=TOGGLE_SET_NEXT; 6=CLEAR_SET_NEXT; 1=TOGGLE_CLEAR_NEXT; 3=TOGGLE
    [15:0] TH — ADV_TIMER1 channel 1 threshold configuration bitfield
  0x54 T1_TH_CHANNEL2 — ADV_TIMER1 channel 2 threshold configuration register
    [18:16] MODE — ADV_TIMER2 channel 1 threshold match action on channel output signal configuration bitfield: - 3'h0: set. - 3'h1: toggle then next threshold match action is clear. - 3'h2: set then next threshold match action is clear. - 3'h3: toggle. - 3'h4: clear. - 3'h5: toggle then next threshold match action is set. - 3'h6: clear then next threshold match action is set.
      values as AdvancedTimer.T0_TH_CHANNEL1.MODE
    [15:0] TH — ADV_TIMER2 channel 1 threshold configuration bitfield
  0x58 T1_TH_CHANNEL3 — ADV_TIMER1 channel 3 threshold configuration register
    [18:16] MODE — ADV_TIMER1 channel 3 threshold match action on channel output signal configuration bitfield: - 3'h0: set. - 3'h1: toggle then next threshold match action is clear. - 3'h2: set then next threshold match action is clear. - 3'h3: toggle. - 3'h4: clear. - 3'h5: toggle then next threshold match action is set. - 3'h6: clear then next threshold match action is set.
      values as AdvancedTimer.T0_TH_CHANNEL1.MODE
    [15:0] TH — ADV_TIMER1 channel 3 threshold configuration bitfield
  0x6C T1_COUNTER ro — ADV_TIMER1 counter register
  {0x8C+4j} T2_TH_CHANNEL{j} (j=0..3) — ADV_TIMER2 channel {j} threshold configuration register
    [18:16] MODE — ADV_TIMER2 channel {j} threshold match action on channel output signal configuration bitfield: - 3'h0: set. - 3'h1: toggle then next threshold match action is clear. - 3'h2: set then next threshold match action is clear. - 3'h3: toggle. - 3'h4: clear. - 3'h5: toggle then next threshold match action is set. - 3'h6: clear then next threshold match action is set.
      values as AdvancedTimer.T0_TH_CHANNEL1.MODE
    [15:0] TH — ADV_TIMER2 channel {j} threshold configuration bitfield
  0xAC T2_COUNTER — ADV_TIMER2 counter register
  {0xCC+4j} T3_TH_CHANNEL{j} (j=0..3) — ADV_TIMER3 channel {j} threshold configuration register
    [18:16] MODE — ADV_TIMER3 channel {j} threshold match action on channel output signal configuration bitfield: - 3'h0: set. - 3'h1: toggle then next threshold match action is clear. - 3'h2: set then next threshold match action is clear. - 3'h3: toggle. - 3'h4: clear. - 3'h5: toggle then next threshold match action is set. - 3'h6: clear then next threshold match action is set.
      values as AdvancedTimer.T0_TH_CHANNEL1.MODE
    [15:0] TH — ADV_TIMER3 channel {j} threshold configuration bitfield
  0xEC T3_COUNTER ro — ADV_TIMER3 counter register
  0x100 EVENT_CFG — ADV_TIMERS events configuration register.
  0x104 CG — ADV_TIMERS channels clock gating configuration register.
    [15:0] ENA — ADV_TIMER clock gating configuration bitfield. - ENA[i]=0: clock gate ADV_TIMERi. - ENA[i]=1: enable ADV_TIMERi.
0x5000 SocEventGenerator group
  0x00 SW_EVENT wo — SoC software events trigger register
    [7:0] EVENT — Writing a one-hot value into EVENT triggers a SoC software event. 8 software events are available.
  {0x4+4j} FC_MASK{j} reset 0xFFFFFFFF (reset mask 0x0) (j=0..5) — Events {32j}-{32j+31} dispatch mask to FC
    [31:0] FC_MASK{j} — Event Mask to enable/disable event dispatch to FC interrupt controller. Setting bit[i] to 0b1 disables dispatching event to FC interrupt controller. Setting bit[i] to 0b0 enables dispatching event to FC interrupt controller.
  0x1C FC_MASK6 reset 0xFFFFFFFF (reset mask 0x0) — Events 191-223 dispatch mask to FC
    [31:0] FC_MASK6 — Event Mask to enable/disable event dispatch to FC interrupt controller. Setting bit[i] to 0b1 disables dispatching event to FC interrupt controller. Setting bit[i] to 0b0 enables dispatching event to FC interrupt controller.
  0x20 FC_MASK7 reset 0xFFFFFFFF (reset mask 0x0) — F Events 224-255 dispatch mask to peripherals
    [31:0] FC_MASK7 — Event Mask to enable/disable event dispatch to FC interrupt controller. Setting bit[i] to 0b1 disables dispatching event to FC interrupt controller. Setting bit[i] to 0b0 enables dispatching event to FC interrupt controller.
  0x44 PR_MASK0 reset 0xFFFFFFFF (reset mask 0x0) — Events 0-31 dispatch mask to peripherals
  0x48 PR_MASK1 reset 0xFFFFFFFF (reset mask 0x0)
    [31:0] PR_MASK1 — Event Mask to enable/disable event dispatch to peripherals. Setting bit[i] to 0b1 disables dispatching event to peripherals. Setting bit[i] to 0b0 enables dispatching event to peripherals.
  0x4C PR_MASK2 reset 0xFFFFFFFF (reset mask 0x0) — Events 0-31 dispatch mask to peripheralsEvents 64-95 dispatch mask to peripherals
    [31:0] PR_MASK2 — Event Mask to enable/disable event dispatch to peripherals. Setting bit[i] to 0b1 disables dispatching event to peripherals. Setting bit[i] to 0b0 enables dispatching event to peripherals.
  0x50 PR_MASK3 reset 0xFFFFFFFF (reset mask 0x0) — Events 96-127 dispatch mask to peripherals
    [31:0] PR_MASK3 — Event Mask to enable/disable event dispatch to peripherals. Setting bit[i] to 0b1 disables dispatching event to peripherals. Setting bit[i] to 0b0 enables dispatching event to peripherals.
  0x54 PR_MASK4 reset 0xFFFFFFFF (reset mask 0x0) — Events 128-159 dispatch mask to peripheral
    [31:0] PR_MASK4 — Event Mask to enable/disable event dispatch to peripherals. Setting bit[i] to 0b1 disables dispatching event to peripherals. Setting bit[i] to 0b0 enables dispatching event to peripherals.
  0x58 PR_MASK5 reset 0xFFFFFFFF (reset mask 0x0) — Events 160-191 dispatch mask to peripherals
    [31:0] PR_MASK5 — Event Mask to enable/disable event dispatch to peripherals. Setting bit[i] to 0b1 disables dispatching event to peripherals. Setting bit[i] to 0b0 enables dispatching event to peripherals.
  0x5C PR_MASK6 reset 0xFFFFFFFF (reset mask 0x0) — Events 191-223 dispatch mask to peripherals
    [31:0] PR_MASK6 — Event Mask to enable/disable event dispatch to peripherals. Setting bit[i] to 0b1 disables dispatching event to peripherals. Setting bit[i] to 0b0 enables dispatching event to peripherals.
  0x60 PR_MASK7 reset 0xFFFFFFFF (reset mask 0x0) — Events 224-255 dispatch mask to peripherals
    [31:0] PR_MASK7 — Event Mask to enable/disable event dispatch to peripherals. Setting bit[i] to 0b1 disables dispatching event to peripherals. Setting bit[i] to 0b0 enables dispatching event to peripherals.
  0x64 ERR0 ro — Events 0-31 event queue overflow
    [31:0] ERR0 — Event queue overflow. Clear after read. Reading 0b1 at ERR[i] means the event queue of event with id i overflowed.
  0x68 ERR1 ro — Events 32-63 event queue overflow
    [31:0] ERR1 — Event queue overflow. Clear after read. Reading 0b1 at ERR[i] means the event queue of event with id i overflowed.
  0x6C ERR2 ro — Events 64-95 event queue overflow
    [31:0] ERR02 — Event queue overflow. Clear after read. Reading 0b1 at ERR[i] means the event queue of event with id i overflowed.
  {0x64+4j} ERR{j} ro (j=3..5) — Events {32j}-{32j+31} event queue overflow
    [31:0] ERR{j} — Event queue overflow. Clear after read. Reading 0b1 at ERR[i] means the event queue of event with id i overflowed.
  0x7C ERR6 ro — Events 191-223 event queue overflow
    [31:0] ERR6 — Event queue overflow. Clear after read. Reading 0b1 at ERR[i] means the event queue of event with id i overflowed.
  0x80 ERR7 ro — Events 224-255 event queue overflow
  0x84 TIMER_LO access not given
    [7:0] TIMER_LO_EVENT — Trigger and start APB Timer LO by the event with id that equals TIMER_LO_EVENT
  0x88 TIMER_HI access not given — Trigger Timer HI of APB Timer with event
    [7:0] TIMER_HI_EVENT — Trigger and start APB Timer HI by the event with id that equals TIMER_HI_EVENT
0x8000 EventInterruptUnit group
  0x00 MASK_read access not given — This register contains the MASK (interrupt enable) for each of the 32 interrupts or events. Writing to 0x1A10_9004 sets the bits of the MASK register selected Writing to 0x1A10_9008 clears the bits of the MASK register selected.
    [31:0] MASK
  0x04 MASK_set access not given — This register contains the MASK (interrupt enable) for each of the 32 interrupts or events. Writing to 0x1A10_9004 sets the bits of the MASK register selected. Writing to 0x1A10_9008 clears the bits of the MASK register selected.
  0x08 MASK_clear access not given — This register contains the MASK (interrupt enable) for each of the 32 interrupts or events. Writing to 0x1A10_9004 sets the bits of the MASK register selected. Writing to 0x1A10_9008 clears the bits of the MASK register selected.
  0x0C INT_read access not given — This register contains the pending interrupts or events. Writing to 0x1A10_9010 sets the bits of the INT register selected. Writing to 0x1A10_9014 clears the bits of the INT register selected.
  0x10 INT_set access not given — INT_read
  0x14 INT_clear access not given
  0x18 ACK_read access not given — This register contains the ACK (interrupt enable) for each of the 32 interrupts or events. Writing to 0x1A10_901C sets the bits of the ACK register selected. Writing to 0x1A10_9020 clears the bits of the ACK register selected.
  0x1C ACK_set access not given — This register contains the ACK (interrupt enable) for each of the 32 interrupts or events. Writing to 0x1A10_901C sets the bits of the ACK register selected. Writing to 0x1A10_9020 clears the bits of the ACK register selected.
  0x20 ACK_clear access not given — This register contains the ACK (interrupt enable) for each of the 32 interrupts or events. Writing to 0x1A10_901C sets the bits of the ACK register selected. Writing to 0x1A10_9020 clears the bits of the ACK register selected.
  0x24 FIFO_DATA ro — Fifo Content. This is a read-only register that contain the first valid value of the FIFO.
    [31:0] FIFO_DATA — This is a read-only register that contain the first valid value of the FIFO
0xA000 Timer group
  0x00 CFG_LO — Timer Low Configuration register
    [31] CASC — Timer low and Timer high 64-bit cascaded mode enable bit
    [15:8] PVAL — Timer low prescaler value. ftimer = fclk/(1 + P V AL)
    [7] CCFG — Timer low clock source configuration 0b0: FLL or FLL plus Prescaler 0b1: 32 kHz reference clock
    [6] PEN — Timer low prescaler enable bit
    [5] ONES — Timer low one shot configuration
    [4] MODE — Timer low continuous mode configuration 0b0: Continue incrementing timer low counter after a compare match with CMP_LO 0b1: Reset timer to after a compare match with CMP_LO
    [2] IRQEN — Timer low interrupt generation on compare match enable
    [1] RST — Timer low reset, cleared after the reset happened
    [0] EN — Timer enable (starts couting) bit
  0x04 CFG_HI — Timer High Configuration register
    [15:8] PVAL — Timer hi prescaler value. ftimer = fclk/(1 + PVAL)
    [7] CCFG — Timer hi clock source configuration 0b0: FLL or FLL plus Prescaler 0b1: 32 kHz reference clock
    [6] PEN — Timer hi prescaler enable bit
    [5] ONES — Timer hi one shot configuration
    [4] MODE — Timer hi continuous mode configuration 0b0: Continue incrementing timer hi counter after a compare match with CMP_HI 0b1: Reset timer to after a compare match with CMP_HI
    [2] IRQEN — Timer hi interrupt generation on compare match enable
    [1] RST — Timer high reset, cleared after the reset happened
    [0] EN — Timer enable (starts couting) bit
  0x08 CNT_LO — Timer Low counter value register
  0x0C CNT_HI — Timer High counter value register
  0x10 CMP_LO — Timer Low comparator value register
  0x14 CMP_HI — Timer High comparator value register
  0x18 START_LO — Start Timer Low counting register
    [0] START_LO — Timer high start command (sets EN in CFG_LO)
  0x1C START_HI — Start Timer High counting register
    [0] START_HI — Timer high reset command (writes RST in CFG_LO)
  0x20 RESET_LO — Reset Timer Low counter register
    [0] RESET_LO
  0x24 RESET_HI — Reset Timer High counter register
    [0] RESET_HI
0x1F000 SDIO group
  0x20 CMD_OP wo
    [13:8] CMD_OPCODE
    [2:0] RSP_TYPE — Values for RSP_TYPE: 3'b000: RSP_TYPE_NULL 3'b001: RSP_TYPE_48_CRC 3'b010: RSP_TYPE_48_NOCRC 3'b011: RSP_TYPE_136 3'b100: RSP_TYPE_48_BSY
      0=RSP_TYPE_NULL; 1=RSP_TYPE_48_CRC; 2=RSP_TYPE_48_NOCRC; 3=RSP_TYPE_136; 4=RSP_TYPE_48_BSY
  0x24 CMD_ARG wo
    [31:0] CMD_ARGUMENT
  0x28 DATA_SETUP wo
    [25:16] BLOCK_SIZE, [15:8] Block_Num, [7:2] QUAD, [1] RWN, [0] EN
  0x2C START wo
    [0] START
  {0x30+4j} RSP{j} ro (j=0..3)
    [31:0] RESPONSE_WORD{j}
  0x40 CLK_DIV_0
    [8] Valid, [7:0] Div_count
  0x44 STATUS reset 0x10 (reset mask 0x0)
    [31:16] Status
    [15:12] VHS — Note: Is reset value correct?
    [11:2] CARD_ERR
    [1] ERR
    [0] EOT
  0x48 CID0 ro — Card Identification Word0
    [31:0] card_id_word0
  {0x48+4j} CID{j} ro (j=1..3) — Card Identification Word {j}
    [31:0] card_id_word{j}
  0x58 RCA ro
    [15:0] RCA
  0x5C STOP wo
    [31] STOP
